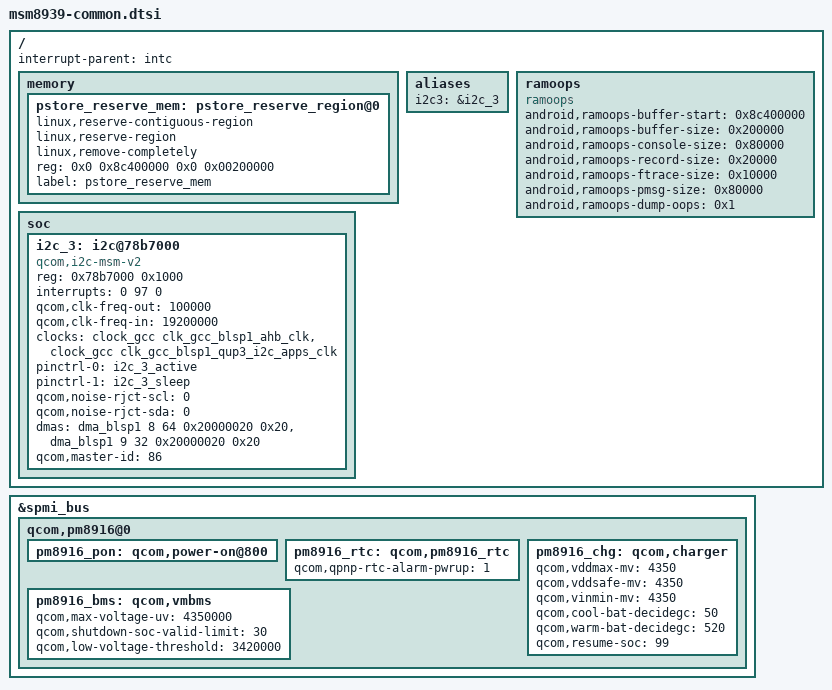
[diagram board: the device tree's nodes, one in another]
/* Copyright (c) 2014, The Linux Foundation. All rights reserved.
 *
 * This program is free software; you can redistribute it and/or modify
 * it under the terms of the GNU General Public License version 2 and
 * only version 2 as published by the Free Software Foundation.
 *
 * This program is distributed in the hope that it will be useful,
 * but WITHOUT ANY WARRANTY; without even the implied warranty of
 * MERCHANTABILITY or FITNESS FOR A PARTICULAR PURPOSE.  See the
 * GNU General Public License for more details.
 */
/ {
	memory {
		pstore_reserve_mem: pstore_reserve_region@0 {
			linux,reserve-contiguous-region;
			linux,reserve-region;
			linux,remove-completely;
			reg = <0x0 0x8c400000 0x0 0x00200000>;
			label = "pstore_reserve_mem";
		};
	};
};
/ {
	interrupt-parent = <&intc>;
	aliases {
		i2c3 = &i2c_3;
	};
	ramoops {
		compatible = "ramoops";
		status = "ok";

		/* This is tracked at the end of pheripheral_region@0 */
		android,ramoops-buffer-start = <0x8c400000>;
		android,ramoops-buffer-size = <0x200000>;
		android,ramoops-console-size = <0x80000>;
		android,ramoops-record-size = <0x20000>;
		android,ramoops-ftrace-size = <0x10000>;
		android,ramoops-pmsg-size = <0x80000>;
		android,ramoops-dump-oops = <0x1>;
	};
	soc: soc { };
};

&soc {
	/delete-node/ serial@78af000;
	// add i2c qup3 (gpio10 gpio11) nx512j add
		i2c_3: i2c@78b7000 { /* BLSP1 QUP3 */
			compatible = "qcom,i2c-msm-v2";
			#address-cells = <1>;
			#size-cells = <0>;
			reg-names = "qup_phys_addr";
			reg = <0x78b7000 0x1000>;
			interrupt-names = "qup_irq";
			interrupts = <0 97 0>;
			qcom,clk-freq-out = <100000>;
			qcom,clk-freq-in  = <19200000>;
			clock-names = "iface_clk", "core_clk";
			clocks = <&clock_gcc clk_gcc_blsp1_ahb_clk>,
				 <&clock_gcc clk_gcc_blsp1_qup3_i2c_apps_clk>;
	
			pinctrl-names = "i2c_active", "i2c_sleep";
			pinctrl-0 = <&i2c_3_active>;
			pinctrl-1 = <&i2c_3_sleep>;
			qcom,noise-rjct-scl = <0>;
			qcom,noise-rjct-sda = <0>;
			dmas = <&dma_blsp1 8 64 0x20000020 0x20>,
				<&dma_blsp1 9 32 0x20000020 0x20>;
			dma-names = "tx", "rx";
			qcom,master-id = <86>;
		};
};

&spmi_bus {
	qcom,pm8916@0 {
		pm8916_pon: qcom,power-on@800 {
		/delete-node/ qcom,pon_2;
		};

		pm8916_rtc: qcom,pm8916_rtc {
			qcom,qpnp-rtc-alarm-pwrup = <1>;
		};

		pm8916_chg: qcom,charger {
			qcom,vddmax-mv = <4350>;  //ZTEMT_CHARGER 4200 --> 4350
			qcom,vddsafe-mv = <4350>;  //ZTEMT_CHARGER 4200 --> 4350
			qcom,vinmin-mv = <4350>;  //ZTEMT_CHARGER 4200 --> 4350
			qcom,cool-bat-decidegc = <50>;  //ZTEMT_CHARGER 100 --> -50
			qcom,warm-bat-decidegc = <520>;  //ZTEMT_CHARGER 450 --> 520
			qcom,resume-soc = <99>;
		};

		pm8916_bms: qcom,vmbms {
			/delete-property/ qcom,resume-soc;
			qcom,max-voltage-uv = <4350000>;  //ZTEMT_CHARGER 4200000 --> 4350000
			qcom,shutdown-soc-valid-limit = <30>;  //ZTEMT_CHARGER 100 --> 30
			qcom,low-voltage-threshold = <3420000>; //ZTEMT_CHARGER 3450000 --> 3420000
		};
	};
};

